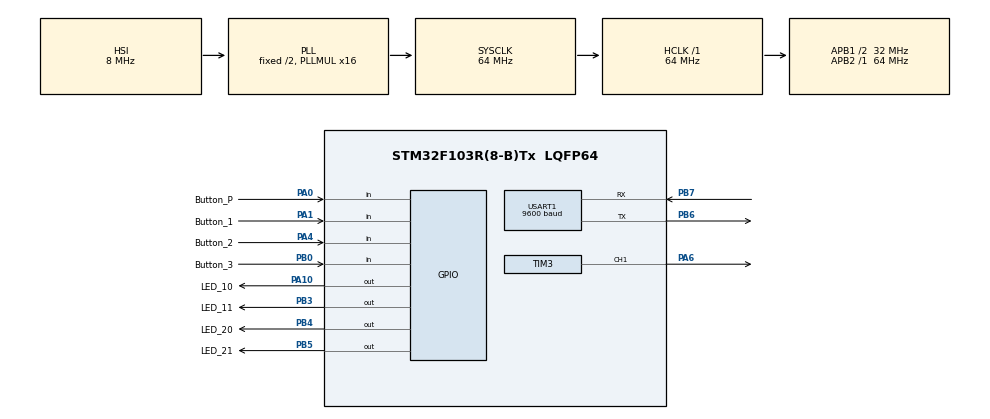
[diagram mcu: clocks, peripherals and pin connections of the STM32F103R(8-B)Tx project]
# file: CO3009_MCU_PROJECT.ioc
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Mcu.Family=STM32F1
Mcu.Name=STM32F103R(8-B)Tx
Mcu.Package=LQFP64
NVIC.PriorityGroup=NVIC_PRIORITYGROUP_4
NVIC.USART1_IRQn=true\:0\:0\:false\:false\:true\:true\:true\:true
PA0-WKUP.GPIO_Label=Button_P
PA0-WKUP.GPIO_PuPd=GPIO_PULLUP
PA0-WKUP.Signal=GPIO_Input
PA1.GPIO_Label=Button_1
PA1.GPIO_PuPd=GPIO_PULLUP
PA1.Signal=GPIO_Input
PA10.GPIO_Label=LED_10
PA10.Signal=GPIO_Output
PA13.Mode=Serial_Wire
PA13.Signal=SYS_JTMS-SWDIO
PA14.Mode=Serial_Wire
PA14.Signal=SYS_JTCK-SWCLK
PA4.GPIO_Label=Button_2
PA4.GPIO_PuPd=GPIO_PULLUP
PA4.Signal=GPIO_Input
PA6.Signal=S_TIM3_CH1
PB0.GPIO_Label=Button_3
PB0.GPIO_PuPd=GPIO_PULLUP
PB0.Signal=GPIO_Input
PB3.GPIO_Label=LED_11
PB3.Signal=GPIO_Output
PB4.GPIO_Label=LED_20
PB4.Signal=GPIO_Output
PB5.GPIO_Label=LED_21
PB5.Signal=GPIO_Output
PB6.Mode=Asynchronous
PB6.Signal=USART1_TX
PB7.Mode=Asynchronous
PB7.Signal=USART1_RX
ProjectManager.HeapSize=0x200
ProjectManager.StackSize=0x400
ProjectManager.TargetToolchain=STM32CubeIDE
RCC.AHBFreq_Value=64000000
RCC.APB1CLKDivider=RCC_HCLK_DIV2
RCC.APB1Freq_Value=32000000
RCC.APB1TimFreq_Value=64000000
RCC.APB2Freq_Value=64000000
RCC.APB2TimFreq_Value=64000000
RCC.HCLKFreq_Value=64000000
RCC.PLLMUL=RCC_PLL_MUL16
RCC.SYSCLKFreq_VALUE=64000000
RCC.SYSCLKSource=RCC_SYSCLKSOURCE_PLLCLK
RCC.USBFreq_Value=64000000
SH.S_TIM3_CH1.0=TIM3_CH1,PWM Generation1 CH1
TIM3.AutoReloadPreload=TIM_AUTORELOAD_PRELOAD_ENABLE
TIM3.Channel-PWM\ Generation1\ CH1=TIM_CHANNEL_1
TIM3.Period=999
TIM3.Prescaler=63
USART1.BaudRate=9600
USART1.VirtualMode=VM_ASYNC
VP_TIM3_VS_ClockSourceINT.Mode=Internal
board=custom

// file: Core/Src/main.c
/* USER CODE BEGIN Header */
/**
  ******************************************************************************
  * @file           : main.c
  * @brief          : Main program body
  ******************************************************************************
  * @attention
  *
  * <h2><center>&copy; Copyright (c) 2022 STMicroelectronics.
  * All rights reserved.</center></h2>
  *
  * This software component is licensed by ST under BSD 3-Clause license,
  * the "License"; You may not use this file except in compliance with the
  * License. You may obtain a copy of the License at:
  *                        opensource.org/licenses/BSD-3-Clause
  *
  ******************************************************************************
  */
/* USER CODE END Header */
#include "main.h"

/* USER CODE BEGIN Includes */
#include "melody.h"
/* USER CODE END Includes */

TIM_HandleTypeDef htim3;

UART_HandleTypeDef huart1;

void SystemClock_Config(void);
static void MX_GPIO_Init(void);
static void MX_TIM3_Init(void);
static void MX_USART1_UART_Init(void);

/* USER CODE BEGIN 0 */
//int signal = 1;
//uint8_t i = 0;
//uint16_t beep[3] = {1,1,1};
//int butterfly[72] = {
//		NOTE_C6, NOTE_C6, NOTE_D6,NOTE_D6, NOTE_E6 ,NOTE_E6, NOTE_C6, NOTE_C6,
//		NOTE_C6,NOTE_C6, NOTE_D6,NOTE_D6, NOTE_E6 ,NOTE_E6, NOTE_C6, 0,
//		NOTE_E6, NOTE_E6, NOTE_F6, NOTE_F6, NOTE_G6,  NOTE_G6, NOTE_G6, NOTE_G6,
//		NOTE_E6, NOTE_E6, NOTE_F6, NOTE_F6, NOTE_G6,  NOTE_G6, NOTE_G6, NOTE_G6,
//		NOTE_G6, NOTE_A6, NOTE_G6, NOTE_F6, NOTE_E6,NOTE_E6, NOTE_C6,NOTE_C6,
//		NOTE_G6, NOTE_A6, NOTE_G6, NOTE_F6, NOTE_E6,NOTE_E6, NOTE_C6,0,
//		NOTE_C6,NOTE_C6,NOTE_G6,NOTE_G6,NOTE_C6,NOTE_C6,NOTE_C6,0,
//		NOTE_C6,NOTE_C6,NOTE_G6,NOTE_G6,NOTE_C6,NOTE_C6,NOTE_C6,0,
//};
//int dio[72] = {
//		NOTE_FS5,NOTE_FS5,0,NOTE_D5,NOTE_D5,0, //6
//		NOTE_D5,NOTE_E5,NOTE_F5,0,	//4
//		NOTE_E5,NOTE_D5,NOTE_CS5,NOTE_D5,//4
//		NOTE_E5,NOTE_FS5,NOTE_FS5,0, //4
//		NOTE_B5,NOTE_B5,0,NOTE_B4, //4
//		NOTE_CS5,NOTE_D5,0, NOTE_E5, //4
//		NOTE_D5, NOTE_CS5, 0, NOTE_A5, NOTE_G5,//6
//		//----------------------
//		NOTE_FS5,NOTE_FS5,0,NOTE_D5,NOTE_D5,0, //6
//		NOTE_D5,NOTE_E5,NOTE_F5,0,	//4
//		NOTE_E5,NOTE_D5,NOTE_CS5,NOTE_D5,//4
//		NOTE_E5,NOTE_FS5,NOTE_FS5,0, //4
//		NOTE_B5,NOTE_B5,0,NOTE_B5, //4
//		NOTE_CS6,NOTE_D6,0, NOTE_G5, //4
//		NOTE_FS5, NOTE_F5, NOTE_D6 , NOTE_AS5, NOTE_B5//6
//};
//uint32_t scale = 0;
//
//void buzzer_sound(){
//	// PSC + 1 => Hz - 31.5
//	//TIM_CCxChannelCmd(&htim3, TIM_CHANNEL_1, TIM_CCx_ENABLE);
//	__HAL_TIM_SET_COMPARE(&htim3,TIM_CHANNEL_1,15 + beep[i%3]);
//	TIM3->PSC = 64000/dio[i%72];// melody[i%3];
//	i++;
//}
/* USER CODE END 0 */

int main(void)
{

  /* MCU Configuration--------------------------------------------------------*/

  /* Reset of all peripherals, Initializes the Flash interface and the Systick. */
  HAL_Init();

  /* Configure the system clock */
  SystemClock_Config();

  /* Initialize all configured peripherals */
  MX_GPIO_Init();
  MX_TIM3_Init();
  MX_USART1_UART_Init();
  /* USER CODE BEGIN 2 */
  HAL_TIM_PWM_Start(&htim3, TIM_CHANNEL_1);
  buzzer_init(TIM3);

  /* USER CODE END 2 */

  /* Infinite loop */
  /* USER CODE BEGIN WHILE */
  while (1)
  {
	  buzzer_sound(htim3, 50);
	  HAL_GPIO_TogglePin(GPIOA, GPIO_PIN_9);
	  HAL_Delay(300);
    /* USER CODE END WHILE */

  }
}

void SystemClock_Config(void)
{
  RCC_OscInitTypeDef RCC_OscInitStruct = {0};
  RCC_ClkInitTypeDef RCC_ClkInitStruct = {0};

  /** Initializes the RCC Oscillators according to the specified parameters
  * in the RCC_OscInitTypeDef structure.
  */
  RCC_OscInitStruct.OscillatorType = RCC_OSCILLATORTYPE_HSI;
  RCC_OscInitStruct.HSIState = RCC_HSI_ON;
  RCC_OscInitStruct.HSICalibrationValue = RCC_HSICALIBRATION_DEFAULT;
  RCC_OscInitStruct.PLL.PLLState = RCC_PLL_ON;
  RCC_OscInitStruct.PLL.PLLSource = RCC_PLLSOURCE_HSI_DIV2;
  RCC_OscInitStruct.PLL.PLLMUL = RCC_PLL_MUL16;
  if (HAL_RCC_OscConfig(&RCC_OscInitStruct) != HAL_OK)
  {
    Error_Handler();
  }
  /** Initializes the CPU, AHB and APB buses clocks
  */
  RCC_ClkInitStruct.ClockType = RCC_CLOCKTYPE_HCLK|RCC_CLOCKTYPE_SYSCLK
                              |RCC_CLOCKTYPE_PCLK1|RCC_CLOCKTYPE_PCLK2;
  RCC_ClkInitStruct.SYSCLKSource = RCC_SYSCLKSOURCE_PLLCLK;
  RCC_ClkInitStruct.AHBCLKDivider = RCC_SYSCLK_DIV1;
  RCC_ClkInitStruct.APB1CLKDivider = RCC_HCLK_DIV2;
  RCC_ClkInitStruct.APB2CLKDivider = RCC_HCLK_DIV1;

  if (HAL_RCC_ClockConfig(&RCC_ClkInitStruct, FLASH_LATENCY_2) != HAL_OK)
  {
    Error_Handler();
  }
}

static void MX_TIM3_Init(void)
{

  TIM_ClockConfigTypeDef sClockSourceConfig = {0};
  TIM_MasterConfigTypeDef sMasterConfig = {0};
  TIM_OC_InitTypeDef sConfigOC = {0};

  htim3.Instance = TIM3;
  htim3.Init.Prescaler = 63;
  htim3.Init.CounterMode = TIM_COUNTERMODE_UP;
  htim3.Init.Period = 999;
  htim3.Init.ClockDivision = TIM_CLOCKDIVISION_DIV1;
  htim3.Init.AutoReloadPreload = TIM_AUTORELOAD_PRELOAD_ENABLE;
  if (HAL_TIM_Base_Init(&htim3) != HAL_OK)
  {
    Error_Handler();
  }
  sClockSourceConfig.ClockSource = TIM_CLOCKSOURCE_INTERNAL;
  if (HAL_TIM_ConfigClockSource(&htim3, &sClockSourceConfig) != HAL_OK)
  {
    Error_Handler();
  }
  if (HAL_TIM_PWM_Init(&htim3) != HAL_OK)
  {
    Error_Handler();
  }
  sMasterConfig.MasterOutputTrigger = TIM_TRGO_RESET;
  sMasterConfig.MasterSlaveMode = TIM_MASTERSLAVEMODE_DISABLE;
  if (HAL_TIMEx_MasterConfigSynchronization(&htim3, &sMasterConfig) != HAL_OK)
  {
    Error_Handler();
  }
  sConfigOC.OCMode = TIM_OCMODE_PWM1;
  sConfigOC.Pulse = 0;
  sConfigOC.OCPolarity = TIM_OCPOLARITY_HIGH;
  sConfigOC.OCFastMode = TIM_OCFAST_DISABLE;
  if (HAL_TIM_PWM_ConfigChannel(&htim3, &sConfigOC, TIM_CHANNEL_1) != HAL_OK)
  {
    Error_Handler();
  }
  HAL_TIM_MspPostInit(&htim3);

}

static void MX_USART1_UART_Init(void)
{

  huart1.Instance = USART1;
  huart1.Init.BaudRate = 9600;
  huart1.Init.WordLength = UART_WORDLENGTH_8B;
  huart1.Init.StopBits = UART_STOPBITS_1;
  huart1.Init.Parity = UART_PARITY_NONE;
  huart1.Init.Mode = UART_MODE_TX_RX;
  huart1.Init.HwFlowCtl = UART_HWCONTROL_NONE;
  huart1.Init.OverSampling = UART_OVERSAMPLING_16;
  if (HAL_UART_Init(&huart1) != HAL_OK)
  {
    Error_Handler();
  }

}

static void MX_GPIO_Init(void)
{
  GPIO_InitTypeDef GPIO_InitStruct = {0};

  /* GPIO Ports Clock Enable */
  __HAL_RCC_GPIOA_CLK_ENABLE();
  __HAL_RCC_GPIOB_CLK_ENABLE();

  /*Configure GPIO pin Output Level */
  HAL_GPIO_WritePin(LED_10_GPIO_Port, LED_10_Pin, GPIO_PIN_RESET);

  /*Configure GPIO pin Output Level */
  HAL_GPIO_WritePin(GPIOB, LED_11_Pin|LED_20_Pin|LED_21_Pin, GPIO_PIN_RESET);

  /*Configure GPIO pins : Button_P_Pin Button_1_Pin Button_2_Pin */
  GPIO_InitStruct.Pin = Button_P_Pin|Button_1_Pin|Button_2_Pin;
  GPIO_InitStruct.Mode = GPIO_MODE_INPUT;
  GPIO_InitStruct.Pull = GPIO_PULLUP;
  HAL_GPIO_Init(GPIOA, &GPIO_InitStruct);

  /*Configure GPIO pin : Button_3_Pin */
  GPIO_InitStruct.Pin = Button_3_Pin;
  GPIO_InitStruct.Mode = GPIO_MODE_INPUT;
  GPIO_InitStruct.Pull = GPIO_PULLUP;
  HAL_GPIO_Init(Button_3_GPIO_Port, &GPIO_InitStruct);

  /*Configure GPIO pin : LED_10_Pin */
  GPIO_InitStruct.Pin = LED_10_Pin;
  GPIO_InitStruct.Mode = GPIO_MODE_OUTPUT_PP;
  GPIO_InitStruct.Pull = GPIO_NOPULL;
  GPIO_InitStruct.Speed = GPIO_SPEED_FREQ_LOW;
  HAL_GPIO_Init(LED_10_GPIO_Port, &GPIO_InitStruct);

  /*Configure GPIO pins : LED_11_Pin LED_20_Pin LED_21_Pin */
  GPIO_InitStruct.Pin = LED_11_Pin|LED_20_Pin|LED_21_Pin;
  GPIO_InitStruct.Mode = GPIO_MODE_OUTPUT_PP;
  GPIO_InitStruct.Pull = GPIO_NOPULL;
  GPIO_InitStruct.Speed = GPIO_SPEED_FREQ_LOW;
  HAL_GPIO_Init(GPIOB, &GPIO_InitStruct);

}

void Error_Handler(void)
{
  __disable_irq();
  while (1)
  {
  }
}

/************************ (C) COPYRIGHT STMicroelectronics *****END OF FILE****/
